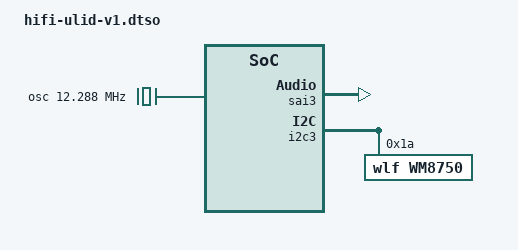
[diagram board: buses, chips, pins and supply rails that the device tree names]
/dts-v1/;
/plugin/;

#include "imx8mm-pinfunc.h"
#include "imx8mm-clock.h"

/ {
	compatible = "gg,kimchi";

	fragment@1 {
		target-path = "/";

		__overlay__ {
			osc: oscillator {
				compatible = "fixed-clock";
				#clock-cells = <1>;
				clock-frequency  = <12288000>;
				clock-output-names = "osc";
			};
		};
	};

	fragment@2 {
		target-path = "/";

		__overlay__ {
			sound-wm8750 {
				compatible = "simple-audio-card";
				simple-audio-card,name = "wm8750-audio";
				simple-audio-card,format = "i2s";
				simple-audio-card,frame-master = <&cpudai>;
				simple-audio-card,bitclock-master = <&cpudai>;
				simple-audio-card,widgets =
					"Headphone", "Headphone Jack",
					"Line", "Line Out Jack";
				simple-audio-card,routing =
					"Headphone Jack", "LOUT1",
					"Headphone Jack", "ROUT1",
					"Line Out Jack", "LOUT2",
					"Line Out Jack", "ROUT2";

				cpudai: simple-audio-card,cpu {
					sound-dai = <&sai3>;
					dai-tdm-slot-num = <2>;
					dai-tdm-slot-width = <32>;
				};

				codecdai: simple-audio-card,codec {
					sound-dai = <&wm8750>;
					clocks = <&clk IMX8MM_CLK_SAI3_ROOT>;
				};
			};
		};
	};

	fragment@3 {
		target = <&sai3>;

		__overlay__ {
			#sound-dai-cells = <0>;
			pinctrl-names = "default";
			pinctrl-0 = <&pinctrl_sai3>;
			assigned-clocks = <&clk IMX8MM_CLK_SAI3>;
			assigned-clock-parents = <&clk IMX8MM_AUDIO_PLL1_OUT>;
			assigned-clock-rates = <12288000>;
			fsl,sai-mclk-direction-output;
			status = "okay";
		};
	};

	fragment@4 {
		target = <&i2c3>;

		__overlay__ {
			#address-cells = <1>;
			#size-cells = <0>;

			wm8750: wm8750@1a {
				#sound-dai-cells = <0>;
				compatible = "wlf,wm8750";
				reg = <0x1a>;
			};
		};
	};

	fragment@5 {
		target = <&iomuxc>;

		__overlay__ {
			pinctrl_sai3: sai3grp {
				fsl,pins = <
					MX8MM_IOMUXC_SAI3_TXFS_SAI3_TX_SYNC     0xd6
					MX8MM_IOMUXC_SAI3_TXC_SAI3_TX_BCLK      0xd6
					MX8MM_IOMUXC_SAI3_MCLK_SAI3_MCLK        0xd6
					MX8MM_IOMUXC_SAI3_TXD_SAI3_TX_DATA0     0xd6
					MX8MM_IOMUXC_SAI3_RXD_SAI3_RX_DATA0     0xd6
				>;
			};
		};
	};
};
